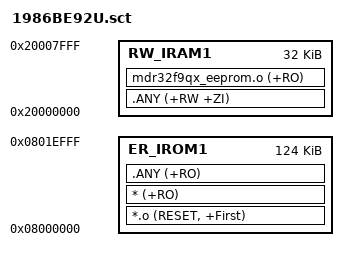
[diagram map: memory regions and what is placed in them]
; *************************************************************
; *** Scatter-Loading Description File generated by uVision ***
; *************************************************************

LR_IROM1 0x08000000 0x00020000-0x100 { ; load region size_region
ER_IROM1 0x08000000 0x00020000-0x1000 { ; load address = execution address
*.o (RESET, +First)
* (+RO)
.ANY (+RO)

}

RW_IRAM1 0x20000000 0x00008000 { ; RW data
.ANY (+RW +ZI)
mdr32f9qx_eeprom.o (+RO)
}
}

;LR_IROM2 (0x0801F000) 0x1000 {
;ER_IROM3 0x0801F000 0x1000 {
;flash_data.o (*)
;}
;}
